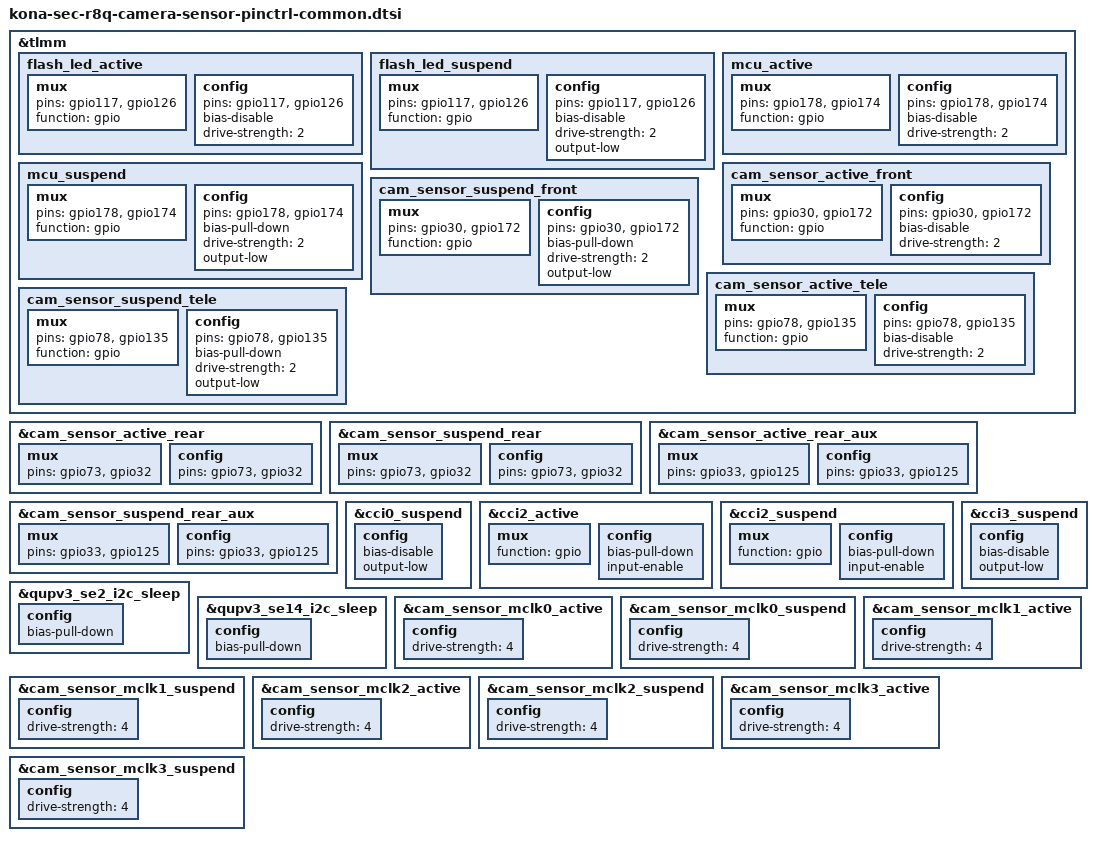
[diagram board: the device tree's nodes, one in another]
/* Copyright (c) 2019, The Linux Foundation. All rights reserved.
 *
 * This program is free software; you can redistribute it and/or modify
 * it under the terms of the GNU General Public License version 2 and
 * only version 2 as published by the Free Software Foundation.
 *
 * This program is distributed in the hope that it will be useful,
 * but WITHOUT ANY WARRANTY; without even the implied warranty of
 * MERCHANTABILITY or FITNESS FOR A PARTICULAR PURPOSE.  See the
 * GNU General Public License for more details.
 */

&tlmm {
	flash_led_active: flash_led_active {
		mux {
			pins = "gpio117","gpio126";
			function = "gpio";
		};

		config {
			pins = "gpio117","gpio126";
			bias-disable; /* No PULL */
			drive-strength = <2>; /* 2 MA */
		};
	};

	flash_led_suspend: flash_led_suspend {
		mux {
			pins = "gpio117","gpio126";
			function = "gpio";
		};

		config {
			pins = "gpio117","gpio126";
			bias-disable; /* No PULL */
			drive-strength = <2>; /* 2 MA */
			output-low;
		};
	};

	mcu_active: mcu_active {
		mux {
			pins = "gpio178","gpio174";
			function = "gpio";
		};

		config {
			pins = "gpio178","gpio174";
			bias-disable; /* No PULL */
			drive-strength = <2>; /* 2 MA */
		};
	};

	mcu_suspend: mcu_suspend {
		mux {
			pins = "gpio178","gpio174";
			function = "gpio";
		};

		config {
			pins = "gpio178","gpio174";
			bias-pull-down; /* PULL DOWN */
			drive-strength = <2>; /* 2 MA */
			output-low;
		};
	};

	cam_sensor_active_front: cam_sensor_active_front {
		/* RESET FRONT */
		mux {
			pins = "gpio30","gpio172";
			function = "gpio";
		};

		config {
			pins = "gpio30","gpio172";
			bias-disable; /* No PULL */
			drive-strength = <2>; /* 2 MA */
		};
	};

	cam_sensor_suspend_front: cam_sensor_suspend_front {
		/* RESET FRONT */
		mux {
			pins = "gpio30","gpio172";
			function = "gpio";
		};

		config {
			pins = "gpio30","gpio172";
			bias-pull-down; /* PULL DOWN */
			drive-strength = <2>; /* 2 MA */
			output-low;
		};
	};

	cam_sensor_active_tele: cam_sensor_active_tele {
		/* RESET TELE */
		mux {
			pins = "gpio78","gpio135";
			function = "gpio";
		};

		config {
			pins = "gpio78","gpio135";
			bias-disable; /* No PULL */
			drive-strength = <2>; /* 2 MA */
		};
	};

	cam_sensor_suspend_tele: cam_sensor_suspend_tele {
		/* RESET TELE */
		mux {
			pins = "gpio78","gpio135";
			function = "gpio";
		};

		config {
			pins = "gpio78","gpio135";
			bias-pull-down; /* PULL DOWN */
			drive-strength = <2>; /* 2 MA */
			output-low;
		};
	};
};

&cam_sensor_active_rear {
	mux {
		pins = "gpio73","gpio32";
	};

	config {
		pins = "gpio73","gpio32";
	};
};

&cam_sensor_suspend_rear {
	mux {
		pins = "gpio73","gpio32";
	};

	config {
		pins = "gpio73","gpio32";
	};
};

&cam_sensor_active_rear_aux {
	mux {
		pins = "gpio33","gpio125";
	};

	config {
		pins = "gpio33","gpio125";
	};
};

&cam_sensor_suspend_rear_aux {
	mux {
		pins = "gpio33","gpio125";
	};

	config {
		pins = "gpio33","gpio125";
	};
};

&cci0_suspend {
	config {
		bias-disable; /* No PULL */
		output-low;
	};
};

&cci2_active {
	mux {
		function = "gpio";
	};
	config {
		bias-pull-down; /* PULL DOWN */
		input-enable;
	};
};

&cci2_suspend {
	mux {
		function = "gpio";
	};
	config {
		bias-pull-down; /* PULL DOWN */
		input-enable;
	};
};

&cci3_suspend {
	config {
		bias-disable; /* No PULL */
		output-low;
	};
};

&qupv3_se2_i2c_sleep {
	config {
		bias-pull-down; /* PULL DOWN */
		/delete-property/ bias-no-pull;
	};
};

&qupv3_se14_i2c_sleep {
	config {
		bias-pull-down; /* PULL DOWN */
		/delete-property/ bias-no-pull;
	};
};

&cam_sensor_mclk0_active {
	config {
		drive-strength = <4>; /* 4 MA */
	};
};

&cam_sensor_mclk0_suspend {
	config {
		drive-strength = <4>; /* 4 MA */
	};
};

&cam_sensor_mclk1_active {
	config {
		drive-strength = <4>; /* 4 MA */
	};
};

&cam_sensor_mclk1_suspend {
	config {
		drive-strength = <4>; /* 4 MA */
	};
};

&cam_sensor_mclk2_active {
	config {
		drive-strength = <4>; /* 4 MA */
	};
};

&cam_sensor_mclk2_suspend {
	config {
		drive-strength = <4>; /* 4 MA */
	};
};

&cam_sensor_mclk3_active {
	config {
		drive-strength = <4>; /* 4 MA */
	};
};

&cam_sensor_mclk3_suspend {
	config {
		drive-strength = <4>; /* 4 MA */
	};
};
